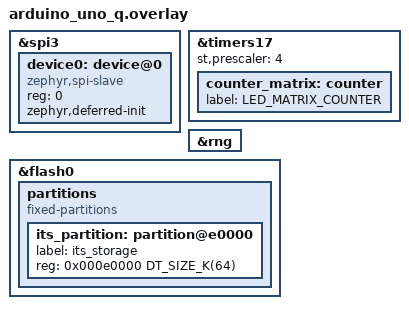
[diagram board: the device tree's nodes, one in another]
/*
 * Device Tree Overlay for Arduino Uno Q PQC Demo
 * 
 * This overlay configures:
 * 1. SPI3 peripheral (slave) for communication with Linux MPU
 * 2. TIM17 counter for LED matrix multiplexing
 */

/* Add SPI slave device to SPI3 */
&spi3 {
	device0: device@0 {
		compatible = "zephyr,spi-slave";
		reg = <0>;
		zephyr,deferred-init;
	};
};

/* Enable TIM17 counter for LED matrix timing */
&timers17 {
	status = "okay";
	st,prescaler = <4>;

	counter_matrix: counter {
		status = "okay";
		label = "LED_MATRIX_COUNTER";
	};
};

/* The LED matrix uses GPIO port F pins PF0-PF10 for charlieplexing.
 * These are configured in the zephyr,user node in the base board DTS.
 * 
 * LED Matrix pin mapping (from ArduinoCore-zephyr):
 *   PF0-PF10: 11 charlieplex control pins for 104 LEDs
 */

/* Enable hardware True Random Number Generator for PQC operations */
&rng {
	status = "okay";
};

/* 
 * Configure storage partition for PSA ITS (Internal Trusted Storage)
 * 
 * The base board DTS already defines storage_partition at 0xe0000 (128KB).
 * We add the 'its_partition' label required by Zephyr Secure Storage subsystem.
 * This allows PSA ITS to store encrypted credentials and keys persistently.
 */
&flash0 {
	partitions {
		compatible = "fixed-partitions";
		#address-cells = <1>;
		#size-cells = <1>;

		/* Add ITS partition label to existing storage partition */
		its_partition: partition@e0000 {
			label = "its_storage";
			reg = <0x000e0000 DT_SIZE_K(64)>;
		};
	};
};
